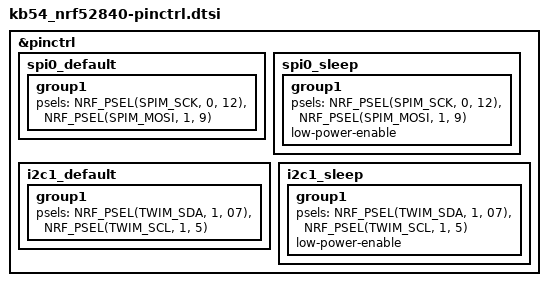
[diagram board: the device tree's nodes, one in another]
&pinctrl {
	spi0_default: spi0_default {
		group1 {
			psels = <NRF_PSEL(SPIM_SCK, 0, 12)>,
				<NRF_PSEL(SPIM_MOSI, 1, 9)>;
		};
	};

	spi0_sleep: spi0_sleep {
		group1 {
			psels = <NRF_PSEL(SPIM_SCK, 0, 12)>,
				<NRF_PSEL(SPIM_MOSI, 1, 9)>;
			low-power-enable;
		};
	};
	
	i2c1_default: i2c1_default {
		group1 {
			psels = <NRF_PSEL(TWIM_SDA, 1, 07)>,
				<NRF_PSEL(TWIM_SCL, 1, 5)>;
		};
	};

	i2c1_sleep: i2c1_sleep {
		group1 {
			psels = <NRF_PSEL(TWIM_SDA, 1, 07)>,
				<NRF_PSEL(TWIM_SCL, 1, 5)>;
			low-power-enable;
		};
	};
};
